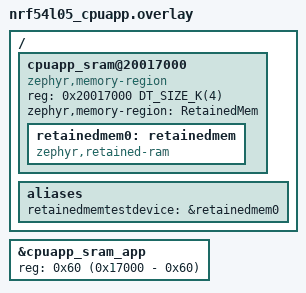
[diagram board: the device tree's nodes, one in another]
/ {
	cpuapp_sram@20017000 {
		compatible = "zephyr,memory-region", "mmio-sram";
		reg = <0x20017000 DT_SIZE_K(4)>;
		ranges = <0x0 0x20017000 DT_SIZE_K(4)>;
		zephyr,memory-region = "RetainedMem";
		status = "okay";
		#address-cells = <1>;
		#size-cells = <1>;

		retainedmem0: retainedmem {
			compatible = "zephyr,retained-ram";
			status = "okay";
			ranges;
			#address-cells = <1>;
			#size-cells = <1>;
		};
	};

	aliases {
		retainedmemtestdevice = &retainedmem0;
	};
};

&cpuapp_sram_app {
	/* Shrink SRAM to avoid overlap with retained memory region. The SRAM ends at
	 * 96 - 4 = 92KB = 0x17000, and starts at 0x60 after the KMU push area, so the
	 * size is that end offset minus 0x60.
	 */
	reg = <0x60 (0x17000 - 0x60)>;
};
